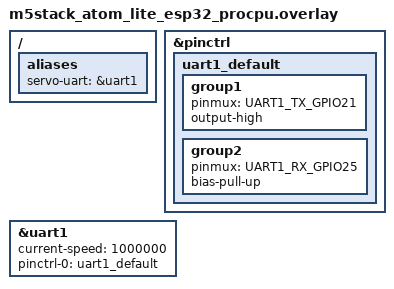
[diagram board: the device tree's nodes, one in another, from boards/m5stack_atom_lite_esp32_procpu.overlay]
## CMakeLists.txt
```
# SPDX-License-Identifier: Apache-2.0

cmake_minimum_required(VERSION 3.20.0)

# Find Zephyr. This also loads Zephyr's build system.
find_package(Zephyr REQUIRED HINTS $ENV{ZEPHYR_BASE})

project(octrobot_firmware VERSION 0.3.0 LANGUAGES C)

# Add application source files
target_sources(app PRIVATE
  src/main.c
)

# Add include directories
target_include_directories(app PRIVATE
  include
)

# HAL layer (Phase 2)
target_sources(app PRIVATE
  src/hal/half_duplex_uart.c
  src/hal/hal_gpio.c
  src/hal/hal_flash.c
)

# Servo driver (Phase 3)
target_sources(app PRIVATE
  src/drivers/feetech_protocol.c
  src/drivers/feetech_servo.c
)

# Host communications (Phase 3b)
target_sources(app PRIVATE
  src/comms/packet_protocol.c
  src/comms/host_comms.c
  src/comms/uart_console.c
)

# Kinematics (Phase 4 - POE implementation)
target_sources(app PRIVATE
  src/kinematics/kinematics_math.c
  src/kinematics/matrix_exp.c
  src/kinematics/robot_geometry.c
  src/kinematics/forward_kinematics_poe.c
  src/kinematics/inverse_kinematics_poe.c
)

# Trajectory planner (to be added in Phase 5)
# target_sources(app PRIVATE
#   src/trajectory/joint_trajectory.c
# )

# Motion controller (to be added in Phase 6)
target_sources(app PRIVATE
  src/controller/servo_control.c
  src/controller/joint_map.c
  src/controller/cartesian_pose.c
  src/controller/cartesian_move.c
)

# Host communications (to be added in Phase 7)
# target_sources(app PRIVATE
#   src/comms/host_comms.c
# )
```

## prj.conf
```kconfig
# OctroBot Robot Arm Firmware Configuration

# Kernel config
CONFIG_MAIN_STACK_SIZE=4096
CONFIG_SYSTEM_WORKQUEUE_STACK_SIZE=2048
CONFIG_HEAP_MEM_POOL_SIZE=8192

# Logging
CONFIG_LOG=y
CONFIG_LOG_DEFAULT_LEVEL=3
CONFIG_LOG_PRINTK=y
CONFIG_LOG_BACKEND_UART=y
CONFIG_CONSOLE=y
CONFIG_UART_CONSOLE=y
# Enable debug level logs for UART console output
CONFIG_UART_CONSOLE_LOG_LEVEL_DBG=y
CONFIG_LOG_MODE_IMMEDIATE=y

# Atom Lite ESP32-PICO-D4 may report chip revision v1.1; allow boot on this revision.
CONFIG_ESP32_USE_UNSUPPORTED_REVISION=y

# Host communication uses UART0 through the onboard CH340 USB-UART bridge
# (ESP32-PICO-D4 doesn't have native USB - only ESP32-S2/S3 have USB)

# UART (UART0 for host commands, UART1 for Feetech servo bus)
CONFIG_SERIAL=y
CONFIG_UART_INTERRUPT_DRIVEN=y

# GPIO (for direction control and emergency stop button)
CONFIG_GPIO=y

# Flash and NVS (Non-Volatile Storage)
CONFIG_FLASH=y
CONFIG_FLASH_MAP=y
CONFIG_NVS=y
CONFIG_NVS_LOG_LEVEL_DBG=y
CONFIG_MPU_ALLOW_FLASH_WRITE=y

# CRC (used by robot_geometry for NVS-stored POE model integrity)
CONFIG_CRC=y

# Timer and system clock
CONFIG_SYS_CLOCK_TICKS_PER_SEC=1000

# Math library support
CONFIG_NEWLIB_LIBC=y
CONFIG_NEWLIB_LIBC_FLOAT_PRINTF=y
CONFIG_NEWLIB_LIBC_FLOAT_SCANF=y

# Dual-core SMP configuration (Phase 4)
# DEBUG 2026-06-02: SMP/APP_CPU bring-up suspected of pre-kernel boot hang
# (RTC/TG0 watchdog loop, no console output). Disabled to isolate. Re-enable
# once dual-core boot is verified on hardware.
CONFIG_SMP=n
CONFIG_MP_MAX_NUM_CPUS=1

# Thread CPU affinity and pinning (selective pinning strategy)
# CONFIG_SCHED_CPU_MASK=y  # requires SMP; re-enable with SMP

# Hardware floating-point unit (critical for matrix operations in FK/IK)
CONFIG_FPU=y
CONFIG_FPU_SHARING=y

# Thread priorities and timing (to be tuned in Phase 6)
# CONFIG_NUM_PREEMPT_PRIORITIES=15

# Zephyr C standard
CONFIG_STD_C17=y
```

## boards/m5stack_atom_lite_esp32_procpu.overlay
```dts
/* Enable dedicated servo UART on Atom Lite (GPIO21 TX, GPIO25 RX). */

#include <zephyr/dt-bindings/pinctrl/esp-pinctrl-common.h>
#include <dt-bindings/pinctrl/esp32-pinctrl.h>

/ {
	aliases {
		servo-uart = &uart1;
	};
};

&pinctrl {
	uart1_default: uart1_default {
		group1 {
			pinmux = <UART1_TX_GPIO21>;
			output-high;
		};
		group2 {
			pinmux = <UART1_RX_GPIO25>;
			bias-pull-up;
		};
	};
};

&uart1 {
	status = "okay";
	current-speed = <1000000>;
	pinctrl-0 = <&uart1_default>;
	pinctrl-names = "default";
};
```

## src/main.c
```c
/*
 * OctroBot Robot Arm Firmware
 * Copyright (c) 2026 OctroBot Project
 *
 * SPDX-License-Identifier: Apache-2.0
 */

#include <inttypes.h>

#include <zephyr/kernel.h>
#include <zephyr/logging/log.h>
#include <zephyr/version.h>

#include "feetech_servo.h"
#include "hal_gpio.h"
#include "hal_flash.h"
#include "half_duplex_uart.h"
#include "uart_console.h"
#include "robot_geometry.h"
#include "forward_kinematics_poe.h"

LOG_MODULE_REGISTER(main, LOG_LEVEL_INF);

static volatile bool emergency_stop_active = false;

static void emergency_stop_callback(void)
{
	emergency_stop_active = true;
	LOG_ERR("!!! EMERGENCY STOP ACTIVATED !!!");

	/* Disable torque on all configured joints. */
	for (uint8_t id = 1; id <= 6; id++) {
		(void)feetech_servo_set_torque_enable(id, false);
	}
}

static int initialize_hal(void)
{
	int ret;

	LOG_INF("Initializing HAL layer...");

	ret = hal_gpio_button_init();
	if (ret == HAL_OK) {
		ret = hal_gpio_button_set_callback(emergency_stop_callback);
		if (ret != HAL_OK) {
			LOG_WRN("Button callback setup failed: %d", ret);
		}
	} else {
		LOG_WRN("Button init failed: %d", ret);
	}

	/* Initialize flash storage for persistent data */
	ret = hal_flash_init();
	if (ret != HAL_OK) {
		LOG_ERR("Failed to initialize flash storage: %d", ret);
		/* Non-fatal - continue without persistent storage */
	}

	struct half_duplex_uart_config uart_config = {
		.device_name = NULL,
		.baudrate = 1000000,
		.tx_timeout_ms = 100,
		.rx_timeout_ms = 50,
	};

	hal_uart_handle_t servo_uart = half_duplex_uart_init(&uart_config);
	if (!servo_uart) {
		LOG_ERR("Failed to initialize half-duplex UART");
		return HAL_ERROR;
	}

	ret = feetech_servo_init(servo_uart);
	if (ret != HAL_OK) {
		LOG_ERR("Failed to initialize servo driver: %d", ret);
		return ret;
	}

	LOG_INF("HAL layer initialized successfully");
	return HAL_OK;
}

static void test_servos(void)
{
	LOG_INF("===========================================");
	LOG_INF("Testing Servo Communication");
	LOG_INF("===========================================");

	uint8_t servo_ids[] = {1, 2, 3, 4, 5, 6};
	uint8_t servo_count = ARRAY_SIZE(servo_ids);
	uint8_t detected_servos = 0;

	LOG_INF("Pinging servos...");
	for (uint8_t i = 0; i < servo_count; i++) {
		int ret = feetech_servo_ping(servo_ids[i]);
		if (ret == HAL_OK) {
			LOG_INF("  Servo %d: OK", servo_ids[i]);
			detected_servos++;
		} else {
			LOG_WRN("  Servo %d: No response (%d)", servo_ids[i], ret);
		}
		k_msleep(50);
	}

	LOG_INF("Detected %d/%d servos", detected_servos, servo_count);
	if (detected_servos == 0) {
		LOG_ERR("No servos detected. Check wiring and power.");
		LOG_INF("  - Verify servos are powered (6-12V)");
		LOG_INF("  - Check UART connections (GPIO 21=TX, GPIO 25=RX)");
		LOG_INF("  - Confirm servo IDs are 1-6");
		LOG_INF("  - Verify baud rate is 1 Mbps");
		return;
	}

	LOG_INF("Reading initial servo positions...");
	for (uint8_t i = 0; i < servo_count; i++) {
		uint16_t position = 0;
		int ret = feetech_servo_read_position(servo_ids[i], &position);
		if (ret == HAL_OK) {
			float angle = FEETECH_POS_TO_DEG(position);
			LOG_INF("  Servo %d: position=%d (%.2f deg)", servo_ids[i], position,
				(double)angle);
		}
		k_msleep(50);
	}

	LOG_INF("Reading servo status...");
	for (uint8_t i = 0; i < servo_count; i++) {
		struct feetech_servo_state state;
		int ret = feetech_servo_read_state(servo_ids[i], &state);
		if (ret == HAL_OK) {
			LOG_INF("  Servo %d: temp=%dC, voltage=%d.%dV, load=%d", servo_ids[i],
				state.present_temperature, state.present_voltage / 10,
				state.present_voltage % 10, state.present_load);
		}
		k_msleep(100);
	}

	LOG_INF("===========================================");
	LOG_INF("Servo test complete");
	LOG_INF("===========================================");
}

static void test_forward_kinematics(void)
{
	LOG_INF("");
	LOG_INF("===========================================");
	LOG_INF("Testing Forward Kinematics (POE)");
	LOG_INF("===========================================");
	
	/* Initialize robot geometry (loads from flash or uses factory defaults) */
	robot_geometry_init();
	const poe_robot_model_t *model = robot_geometry_get_model();
	
	LOG_INF("Robot model loaded:");
	LOG_INF("  - Screw axes: 6 joints");
	LOG_INF("  - Home config: M matrix");
	LOG_INF("  - Joint limits configured");
	
	/* Test 1: Zero configuration (home position) */
	LOG_INF("");
	LOG_INF("Test 1: Zero configuration (home position)");
	float joint_angles_zero[NUM_JOINTS] = {0.0f, 0.0f, 0.0f, 0.0f, 0.0f, 0.0f};
	mat4x4_t T_zero;
	
	if (forward_kinematics_compute(model, joint_angles_zero, &T_zero)) {
		vec3_t pos = mat4x4_get_translation(&T_zero);
		LOG_INF("  FK([0,0,0,0,0,0]):");
		LOG_INF("    Position: [%.4f, %.4f, %.4f] m", 
		        (double)pos.x, (double)pos.y, (double)pos.z);
		LOG_INF("    (Should match home configuration M)");
	} else {
		LOG_ERR("  FK computation failed!");
	}
	
	/* Test 2: Small joint movements */
	LOG_INF("");
	LOG_INF("Test 2: Small joint movements");
	float joint_angles_30deg[NUM_JOINTS] = {
		deg_to_rad(30.0f),   /* Base rotation 30° */
		deg_to_rad(0.0f),    /* Shoulder */
		deg_to_rad(0.0f),    /* Elbow */
		deg_to_rad(0.0f),    /* Wrist roll */
		deg_to_rad(0.0f),    /* Wrist pitch */
		deg_to_rad(0.0f)     /* Wrist roll */
	};
	mat4x4_t T_30deg;
	
	if (forward_kinematics_compute(model, joint_angles_30deg, &T_30deg)) {
		vec3_t pos = mat4x4_get_translation(&T_30deg);
		LOG_INF("  FK([30°,0,0,0,0,0]):");
		LOG_INF("    Position: [%.4f, %.4f, %.4f] m", 
		        (double)pos.x, (double)pos.y, (double)pos.z);
		LOG_INF("    (Base rotated 30°, end-effector should move in XY plane)");
	} else {
		LOG_ERR("  FK computation failed!");
	}
	
	/* Test 3: Multiple joint movements */
	LOG_INF("");
	LOG_INF("Test 3: Multiple joint movements");
	float joint_angles_multi[NUM_JOINTS] = {
		deg_to_rad(45.0f),   /* Base 45° */
		deg_to_rad(30.0f),   /* Shoulder 30° */
		deg_to_rad(-20.0f),  /* Elbow -20° */
		deg_to_rad(0.0f),    /* Wrist roll */
		deg_to_rad(15.0f),   /* Wrist pitch 15° */
		deg_to_rad(0.0f)     /* Wrist roll */
	};
	mat4x4_t T_multi;
	
	if (forward_kinematics_compute(model, joint_angles_multi, &T_multi)) {
		vec3_t pos = mat4x4_get_translation(&T_multi);
		mat3x3_t rot = mat4x4_get_rotation(&T_multi);
		LOG_INF("  FK([45°,30°,-20°,0°,15°,0°]):");
		LOG_INF("    Position: [%.4f, %.4f, %.4f] m", 
		        (double)pos.x, (double)pos.y, (double)pos.z);
		LOG_INF("    Rotation matrix:");
		LOG_INF("      [%.3f, %.3f, %.3f]", 
		        (double)rot.m[0][0], (double)rot.m[0][1], (double)rot.m[0][2]);
		LOG_INF("      [%.3f, %.3f, %.3f]", 
		        (double)rot.m[1][0], (double)rot.m[1][1], (double)rot.m[1][2]);
		LOG_INF("      [%.3f, %.3f, %.3f]", 
		        (double)rot.m[2][0], (double)rot.m[2][1], (double)rot.m[2][2]);
	} else {
		LOG_ERR("  FK computation failed!");
	}
	
	/* Test 4: Partial FK (intermediate link positions) */
	LOG_INF("");
	LOG_INF("Test 4: Partial FK (joint 2 position)");
	mat4x4_t T_partial;
	
	if (forward_kinematics_partial(model, joint_angles_multi, 2, &T_partial)) {
		vec3_t pos = mat4x4_get_translation(&T_partial);
		LOG_INF("  FK_partial([45°,30°,-20°,...], end_idx=2):");
		LOG_INF("    Joint 2 position: [%.4f, %.4f, %.4f] m", 
		        (double)pos.x, (double)pos.y, (double)pos.z);
		LOG_INF("    (Position after joints 0-2)");
	} else {
		LOG_ERR("  Partial FK computation failed!");
	}
	
	/* Test 5: Performance measurement */
	LOG_INF("");
	LOG_INF("Test 5: Performance measurement");
	uint32_t start_time = k_cycle_get_32();
	const int num_iterations = 100;
	
	for (int i = 0; i < num_iterations; i++) {
		mat4x4_t T_perf;
		forward_kinematics_compute(model, joint_angles_multi, &T_perf);
	}
	
	uint32_t end_time = k_cycle_get_32();
	uint32_t cycles = end_time - start_time;
	uint32_t cycles_per_fk = cycles / num_iterations;
	
	/* ESP32 @ 240MHz: 1 cycle = 1/240MHz ≈ 4.17 ns */
	float time_per_fk_us = (float)cycles_per_fk / 240.0f;  /* μs */
	
	LOG_INF("  FK computation time:");
	LOG_INF("    %d iterations: %u cycles", num_iterations, cycles);
	LOG_INF("    Average: %u cycles/FK (%.2f μs)", 
	        cycles_per_fk, (double)time_per_fk_us);
	LOG_INF("    Expected: 2000-5000 μs (2-5 ms)");
	
	if (time_per_fk_us < 10000.0f) {  /* Less than 10ms */
		LOG_INF("    ✓ Performance is good!");
	} else {
		LOG_WRN("    ⚠ Performance is slower than expected");
	}
	
	LOG_INF("");
	LOG_INF("===========================================");
	LOG_INF("Forward Kinematics test complete");
	LOG_INF("===========================================");
}

int main(void)
{
	int ret;

	LOG_INF("===========================================");
	LOG_INF("OctroBot Robot Arm Firmware v0.3.0");
	LOG_INF("===========================================");
	LOG_INF("MCU: ESP32-PICO-D4 (M5Stack Atom Lite)");
	LOG_INF("RTOS: Zephyr RTOS v%s", KERNEL_VERSION_STRING);
	LOG_INF("Build: %s %s", __DATE__, __TIME__);
	LOG_INF("Console: UART0 via CH340 USB-UART bridge");
	LOG_INF("===========================================");

	ret = initialize_hal();
	if (ret != HAL_OK) {
		LOG_ERR("HAL initialization failed: %d", ret);
		return ret;
	}

	LOG_INF("System initialization complete");
	LOG_INF("6-DOF robot arm ready");
	LOG_INF("Press button (GPIO 39) for emergency stop");

	k_sleep(K_MSEC(500));
	test_servos();
	
	/* Test forward kinematics (Phase 4) */
	k_sleep(K_MSEC(500));
	test_forward_kinematics();

	/* Initialize host communication */
	ret = uart_console_init();
	if (ret == 0) {
		LOG_INF("Host communication initialized");
		LOG_INF("Connect via USB serial to send commands");
	} else {
		LOG_WRN("Host communication init failed: %d", ret);
		LOG_INF("Continuing without host control...");
	}

	LOG_INF("");
	LOG_INF("===========================================");
	LOG_INF("Entering main loop - Phase 3b Manual Control");
	LOG_INF("===========================================");
	LOG_INF("Send commands via USB serial to control robot");
	LOG_INF("Available commands:");
	LOG_INF("  - jog: Move joints incrementally");
	LOG_INF("  - set: Direct position control");
	LOG_INF("  - read: Get current joint angles");
	LOG_INF("  - demo: Record and playback motions");
	LOG_INF("===========================================");
	LOG_INF("");

	while (1) {
		// Heartbeat message every 5 seconds
		LOG_DBG("Main loop heartbeat");
		k_sleep(K_MSEC(5000));
	}

	return 0;
}
```

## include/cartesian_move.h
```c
/*
 * OctroBot Robot Arm Firmware - Cartesian Move-to-Pose (hardware wrapper)
 * Copyright (c) 2026 OctroBot Project
 *
 * SPDX-License-Identifier: Apache-2.0
 *
 * Drives the arm to a commanded Cartesian pose: checks e-stop, reads the
 * current servo angles for the IK seed, runs cartesian_pose_to_joints, maps the
 * solution to servo degrees, range-checks, and sync-writes goal angles with an
 * onboard move time. RPY is ZYX intrinsic (degrees); position in meters.
 */

#ifndef CARTESIAN_MOVE_H
#define CARTESIAN_MOVE_H

#include <stdint.h>
#include "cartesian_pose.h"   /* cmove_status_t */

#ifdef __cplusplus
extern "C" {
#endif

/**
 * Move the arm to a Cartesian pose.
 *
 * @param x,y,z       target position in meters (model frame)
 * @param roll_deg,pitch_deg,yaw_deg  target orientation, ZYX intrinsic, degrees
 * @param move_time_ms  servo move duration in ms (onboard smoothing)
 * @return cmove_status_t (CMOVE_OK on success; no motion is commanded on any
 *         non-OK status)
 */
cmove_status_t cartesian_move_to_pose(float x, float y, float z,
				      float roll_deg, float pitch_deg,
				      float yaw_deg, uint16_t move_time_ms);

#ifdef __cplusplus
}
#endif

#endif /* CARTESIAN_MOVE_H */
```

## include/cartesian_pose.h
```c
/*
 * OctroBot Robot Arm Firmware - Cartesian Pose -> Joints (pure core)
 * Copyright (c) 2026 OctroBot Project
 *
 * SPDX-License-Identifier: Apache-2.0
 *
 * Pure (hardware-free) conversion of a commanded Cartesian pose into
 * model-frame joint angles via the IK solver. RPY uses the ZYX intrinsic
 * convention; angles in degrees, position in meters.
 */

#ifndef CARTESIAN_POSE_H
#define CARTESIAN_POSE_H

#include "robot_geometry.h"   /* poe_robot_model_t, NUM_JOINTS */

#ifdef __cplusplus
extern "C" {
#endif

/** Result of a Cartesian move-to-pose request. */
typedef enum {
	CMOVE_OK = 0,         /* solved (and, in the wrapper, motion sent)     */
	CMOVE_NO_SOLUTION,    /* IK did not converge                           */
	CMOVE_OUT_OF_LIMITS,  /* solution violates joint/servo limits          */
	CMOVE_ESTOP,          /* emergency stop active (wrapper only)          */
	CMOVE_SERVO_ERR,      /* servo read/write failure (wrapper only)       */
	CMOVE_BAD_ARGS,       /* NULL/invalid argument                         */
} cmove_status_t;

/**
 * Compute model-frame joint angles for a Cartesian pose.
 *
 * @param model       robot geometry
 * @param x,y,z       target position in meters (model frame)
 * @param roll_deg,pitch_deg,yaw_deg  target orientation, ZYX intrinsic, degrees
 * @param seed_theta  IK initial guess (model radians)
 * @param out_theta   solved joint angles (model radians)
 * @param iters_used  if non-NULL, receives the IK iteration count (debug)
 * @return CMOVE_OK / CMOVE_NO_SOLUTION / CMOVE_OUT_OF_LIMITS / CMOVE_BAD_ARGS.
 *         out_theta is written on both CMOVE_OK and CMOVE_OUT_OF_LIMITS (the
 *         final IK iterate); it is left untouched on the other statuses.
 *         Callers must not command motion unless the status is CMOVE_OK.
 */
cmove_status_t cartesian_pose_to_joints(const poe_robot_model_t *model,
					float x, float y, float z,
					float roll_deg, float pitch_deg,
					float yaw_deg,
					const float seed_theta[NUM_JOINTS],
					float out_theta[NUM_JOINTS],
					int *iters_used);

#ifdef __cplusplus
}
#endif

#endif /* CARTESIAN_POSE_H */
```

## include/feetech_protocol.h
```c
/*
 * OctroBot Robot Arm Firmware - Feetech SCS/STS Protocol
 * Copyright (c) 2026 OctroBot Project
 *
 * SPDX-License-Identifier: Apache-2.0
 *
 * Protocol implementation for Feetech Serial Control System (SCS) and
 * Serial Torque Servo (STS) servos.
 *
 * Packet Format:
 *   [0xFF] [0xFF] [ID] [LENGTH] [INSTRUCTION] [PARAMS...] [CHECKSUM]
 *
 * Checksum: ~(ID + LENGTH + INSTRUCTION + PARAMS) & 0xFF
 */

#ifndef OCTROBOT_FEETECH_PROTOCOL_H
#define OCTROBOT_FEETECH_PROTOCOL_H

#include "hal_types.h"
#include "half_duplex_uart.h"

/* Protocol constants */
#define FEETECH_HEADER_1          0xFF
#define FEETECH_HEADER_2          0xFF
#define FEETECH_BROADCAST_ID      0xFE
#define FEETECH_MIN_PACKET_SIZE   6

/* Instruction set */
#define FEETECH_INST_PING         0x01
#define FEETECH_INST_READ         0x02
#define FEETECH_INST_WRITE        0x03
#define FEETECH_INST_REG_WRITE    0x04
#define FEETECH_INST_ACTION       0x05
#define FEETECH_INST_SYNC_WRITE   0x83
#define FEETECH_INST_SYNC_READ    0x84

/* Common register addresses (STS series) */
#define FEETECH_REG_ID                    0x05
#define FEETECH_REG_BAUD_RATE             0x06
#define FEETECH_REG_RETURN_DELAY          0x07
#define FEETECH_REG_RESPONSE_STATUS       0x08
#define FEETECH_REG_MIN_ANGLE_LIMIT_L     0x09
#define FEETECH_REG_MIN_ANGLE_LIMIT_H     0x0A
#define FEETECH_REG_MAX_ANGLE_LIMIT_L     0x0B
#define FEETECH_REG_MAX_ANGLE_LIMIT_H     0x0C
#define FEETECH_REG_MAX_TEMPERATURE       0x0D
#define FEETECH_REG_MAX_VOLTAGE           0x0E
#define FEETECH_REG_MIN_VOLTAGE           0x0F
#define FEETECH_REG_MAX_TORQUE_L          0x10
#define FEETECH_REG_MAX_TORQUE_H          0x11
#define FEETECH_REG_UNLOAD_CONDITION      0x13
#define FEETECH_REG_LED_ALARM             0x14
#define FEETECH_REG_P_COEFFICIENT         0x15
#define FEETECH_REG_D_COEFFICIENT         0x16
#define FEETECH_REG_I_COEFFICIENT         0x17
#define FEETECH_REG_MINIMUM_STARTUP_FORCE_L 0x18
#define FEETECH_REG_MINIMUM_STARTUP_FORCE_H 0x19
#define FEETECH_REG_TORQUE_ENABLE         0x28
#define FEETECH_REG_ACCELERATION          0x29
#define FEETECH_REG_GOAL_POSITION_L       0x2A
#define FEETECH_REG_GOAL_POSITION_H       0x2B
#define FEETECH_REG_GOAL_TIME_L           0x2C
#define FEETECH_REG_GOAL_TIME_H           0x2D
#define FEETECH_REG_GOAL_SPEED_L          0x2E
#define FEETECH_REG_GOAL_SPEED_H          0x2F
#define FEETECH_REG_TORQUE_LIMIT_L        0x30
#define FEETECH_REG_TORQUE_LIMIT_H        0x31
#define FEETECH_REG_LOCK                  0x37
#define FEETECH_REG_PRESENT_POSITION_L    0x38
#define FEETECH_REG_PRESENT_POSITION_H    0x39
#define FEETECH_REG_PRESENT_SPEED_L       0x3A
#define FEETECH_REG_PRESENT_SPEED_H       0x3B
#define FEETECH_REG_PRESENT_LOAD_L        0x3C
#define FEETECH_REG_PRESENT_LOAD_H        0x3D
#define FEETECH_REG_PRESENT_VOLTAGE       0x3E
#define FEETECH_REG_PRESENT_TEMPERATURE   0x3F
#define FEETECH_REG_REGISTERED            0x40
#define FEETECH_REG_STATUS                0x41
#define FEETECH_REG_MOVING                0x42
#define FEETECH_REG_VIR_POSITION_L        0x46
#define FEETECH_REG_VIR_POSITION_H        0x47
#define FEETECH_REG_CURRENT_L             0x45
#define FEETECH_REG_CURRENT_H             0x69

/* Error codes in response packets */
#define FEETECH_ERROR_VOLTAGE       (1 << 0)
#define FEETECH_ERROR_ANGLE_LIMIT   (1 << 1)
#define FEETECH_ERROR_OVERHEAT      (1 << 2)
#define FEETECH_ERROR_RANGE         (1 << 3)
#define FEETECH_ERROR_CHECKSUM      (1 << 4)
#define FEETECH_ERROR_OVERLOAD      (1 << 5)
#define FEETECH_ERROR_INSTRUCTION   (1 << 6)

/* Maximum packet size */
#define FEETECH_MAX_PACKET_SIZE   256

/**
 * @brief Feetech packet structure
 */
struct feetech_packet {
	uint8_t id;
	uint8_t instruction;
	uint8_t error;
	uint8_t parameters[FEETECH_MAX_PACKET_SIZE];
	uint8_t param_length;
};

/**
 * @brief Calculate checksum for Feetech packet
 *
 * @param id Servo ID
 * @param length Packet length (instruction + params + 1)
 * @param instruction Instruction byte
 * @param params Parameter bytes
 * @param param_len Number of parameter bytes
 * @return Calculated checksum
 */
uint8_t feetech_protocol_calculate_checksum(uint8_t id, uint8_t length, uint8_t instruction,
                                    const uint8_t *params, uint8_t param_len);

/**
 * @brief Build a Feetech instruction packet
 *
 * @param packet Pointer to packet structure
 * @param buffer Output buffer for raw packet bytes
 * @param buffer_size Size of output buffer
 * @return Number of bytes written to buffer, or negative error code
 */
int feetech_protocol_build_packet(const struct feetech_packet *packet, uint8_t *buffer,
                         size_t buffer_size);

/**
 * @brief Parse a Feetech response packet
 *
 * @param buffer Input buffer containing raw packet bytes
 * @param buffer_len Length of input buffer
 * @param packet Pointer to packet structure to fill
 * @return HAL_OK on success, error code otherwise
 */
int feetech_protocol_parse_packet(const uint8_t *buffer, size_t buffer_len,
                         struct feetech_packet *packet);

/**
 * @brief Send a ping to servo and wait for response
 *
 * @param uart UART handle
 * @param id Servo ID
 * @return HAL_OK if servo responds, error code otherwise
 */
int feetech_protocol_ping(hal_uart_handle_t uart, uint8_t id);

/**
 * @brief Read data from servo register
 *
 * @param uart UART handle
 * @param id Servo ID
 * @param reg_addr Register address
 * @param length Number of bytes to read
 * @param data Output buffer for read data
 * @return HAL_OK on success, error code otherwise
 */
int feetech_protocol_read(hal_uart_handle_t uart, uint8_t id, uint8_t reg_addr,
                 uint8_t length, uint8_t *data);

/**
 * @brief Write data to servo register
 *
 * @param uart UART handle
 * @param id Servo ID
 * @param reg_addr Register address
 * @param data Data to write
 * @param length Number of bytes to write
 * @return HAL_OK on success, error code otherwise
 */
int feetech_protocol_write(hal_uart_handle_t uart, uint8_t id, uint8_t reg_addr,
                  const uint8_t *data, uint8_t length);

/**
 * @brief Sync write to multiple servos (single register)
 *
 * @param uart UART handle
 * @param reg_addr Starting register address
 * @param data_len Length of data per servo
 * @param servo_ids Array of servo IDs
 * @param servo_data Array of data for each servo (servo_count * data_len bytes)
 * @param servo_count Number of servos
 * @return HAL_OK on success, error code otherwise
 */
int feetech_protocol_sync_write(hal_uart_handle_t uart, uint8_t reg_addr, uint8_t data_len,
                       const uint8_t *servo_ids, const uint8_t *servo_data,
                       uint8_t servo_count);

/**
 * @brief Read 16-bit value from servo (little-endian)
 *
 * @param uart UART handle
 * @param id Servo ID
 * @param reg_addr Register address (low byte)
 * @param value Pointer to store 16-bit value
 * @return HAL_OK on success, error code otherwise
 */
int feetech_protocol_read_word(hal_uart_handle_t uart, uint8_t id, uint8_t reg_addr,
                      uint16_t *value);

/**
 * @brief Write 16-bit value to servo (little-endian)
 *
 * @param uart UART handle
 * @param id Servo ID
 * @param reg_addr Register address (low byte)
 * @param value 16-bit value to write
 * @return HAL_OK on success, error code otherwise
 */
int feetech_protocol_write_word(hal_uart_handle_t uart, uint8_t id, uint8_t reg_addr,
                       uint16_t value);

#endif /* OCTROBOT_FEETECH_PROTOCOL_H */
```

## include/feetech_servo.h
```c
/*
 * OctroBot Robot Arm Firmware - Feetech Servo Driver
 * Copyright (c) 2026 OctroBot Project
 *
 * SPDX-License-Identifier: Apache-2.0
 *
 * High-level servo control API for Feetech SCS/STS servos.
 */

#ifndef OCTROBOT_FEETECH_SERVO_H
#define OCTROBOT_FEETECH_SERVO_H

#include "hal_types.h"
#include "half_duplex_uart.h"

/* Servo position range (typical for STS3215) */
#define FEETECH_POS_MIN      0
#define FEETECH_POS_MAX      4095
#define FEETECH_POS_CENTER   2048

/* Convert between servo ticks and degrees */
#define FEETECH_POS_TO_DEG(pos)   (((float)(pos) - FEETECH_POS_CENTER) * (360.0f / 4096.0f))
#define FEETECH_DEG_TO_POS(deg)   ((uint16_t)(((deg) * (4096.0f / 360.0f)) + FEETECH_POS_CENTER))

/* Velocity range (typical for STS3215) */
#define FEETECH_VEL_MIN      0
#define FEETECH_VEL_MAX      4095
#define FEETECH_DEFAULT_SPEED 1000  /* Default speed in steps/second (~50% max) */

/* Speed clamp for time-based moves. These servos move under GOAL_SPEED, not
 * GOAL_TIME, and a speed of 0 means "hold" (no motion). The floor guarantees
 * even tiny moves actuate; the cap keeps bring-up moves gentle. */
#define FEETECH_TIMED_SPEED_MIN  50
#define FEETECH_TIMED_SPEED_MAX  2000

/* Maximum number of servos in robot */
#define FEETECH_MAX_SERVOS   6

/**
 * @brief Servo configuration structure
 */
struct feetech_servo_config {
	uint8_t id;                     /* Servo ID (1-253) */
	uint16_t pos_min;               /* Minimum position limit (ticks) */
	uint16_t pos_max;               /* Maximum position limit (ticks) */
	uint16_t pos_offset;            /* Position offset for calibration */
	bool reverse;                   /* Reverse direction flag */
};

/**
 * @brief Servo state structure
 */
struct feetech_servo_state {
	uint16_t present_position;      /* Current position (ticks) */
	uint16_t present_speed;         /* Current speed */
	uint16_t present_load;          /* Current load */
	uint8_t present_voltage;        /* Current voltage (0.1V units) */
	uint8_t present_temperature;    /* Current temperature (°C) */
	bool is_moving;                 /* Movement status */
	bool is_torque_enabled;         /* Torque status */
	uint8_t error;                  /* Error flags */
};

/**
 * @brief Initialize Feetech servo driver
 *
 * @param uart UART handle for servo communication
 * @return HAL_OK on success, error code otherwise
 */
int feetech_servo_init(hal_uart_handle_t uart);

/**
 * @brief Ping servo to check if it's responding
 *
 * @param id Servo ID
 * @return HAL_OK if servo responds, error code otherwise
 */
int feetech_servo_ping(uint8_t id);

/**
 * @brief Enable/disable servo torque
 *
 * @param id Servo ID
 * @param enable true to enable torque, false to disable
 * @return HAL_OK on success, error code otherwise
 */
int feetech_servo_set_torque_enable(uint8_t id, bool enable);

/**
 * @brief Check if servo torque is currently enabled
 * @param id Servo ID
 * @return true if torque is enabled, false if disabled or on error
 */
bool feetech_servo_is_torque_enabled(uint16_t id);

/**
 * @brief Set torque limit for servo at runtime instead of using EEPROM settings
 * @param id Servo ID
 * @param max_torque Maximum torque (0-1000, where 1000 = 100%)
 * @return HAL_OK on success, error code otherwise
 */
int feetech_servo_set_torque_limit(uint8_t id, uint16_t max_torque);

/**
 * @brief Read current torque limit setting from servo
 * @param id Servo ID
 * @param max_torque Pointer to store maximum torque (0-1000, where 1000 = 100%)
 * @return HAL_OK on success, error code otherwise
 */
int feetech_servo_read_torque_limit(uint8_t id, uint16_t *max_torque);

/**
 * @brief Set servo goal position (in ticks)
 *
 * Sets goal position with default time (0 = immediate) and default speed
 * (FEETECH_DEFAULT_SPEED = 2000 steps/second).
 * Uses optimized 6-byte write per Feetech protocol (0x2A-0x2F).
 *
 * @param id Servo ID
 * @param position Goal position (0-4095)
 * @return HAL_OK on success, error code otherwise
 */
int feetech_servo_set_goal_position(uint8_t id, uint16_t position);

/**
 * @brief Set servo goal position with time and speed control (extended)
 *
 * Sets position, time, and speed in single 6-byte write to 0x2A-0x2F
 * per Feetech protocol. More efficient than separate writes.
 *
 * @param id Servo ID
 * @param position Goal position (0-4095)
 * @param time_ms Time to reach position in milliseconds (0 = immediate)
 * @param speed Maximum speed during movement in steps/second (0 = no limit)
 * @return HAL_OK on success, error code otherwise
 */
int feetech_servo_set_goal_position_ex(uint8_t id, uint16_t position,
                                        uint16_t time_ms, uint16_t speed);

/**
 * @brief Set servo goal position (in degrees)
 *
 * @param id Servo ID
 * @param angle Goal angle in degrees (-180 to +180)
 * @return HAL_OK on success, error code otherwise
 */
int feetech_servo_set_goal_angle(uint8_t id, float angle);

/**
 * @brief Set servo goal speed
 *
 * @param id Servo ID
 * @param speed Goal speed (0-4095)
 * @return HAL_OK on success, error code otherwise
 */
int feetech_servo_set_goal_speed(uint8_t id, uint16_t speed);

/**
 * @brief Set servo goal time (trajectory duration)
 *
 * @param id Servo ID
 * @param time_ms Goal time in milliseconds
 * @return HAL_OK on success, error code otherwise
 */
int feetech_servo_set_goal_time(uint8_t id, uint16_t time_ms);

/**
 * @brief Set servo acceleration
 *
 * @param id Servo ID
 * @param acceleration Acceleration value (0-254)
 * @return HAL_OK on success, error code otherwise
 */
int feetech_servo_set_acceleration(uint8_t id, uint8_t acceleration);

/**
 * @brief Read servo current position (in ticks)
 *
 * @param id Servo ID
 * @param position Pointer to store position
 * @return HAL_OK on success, error code otherwise
 */
int feetech_servo_read_position(uint8_t id, uint16_t *position);

/**
 * @brief Read servo current position (in degrees)
 *
 * @param id Servo ID
 * @param angle Pointer to store angle in degrees
 * @return HAL_OK on success, error code otherwise
 */
int feetech_servo_read_angle(uint8_t id, float *angle);

/**
 * @brief Read servo load (torque feedback)
 *
 * @param id Servo ID
 * @param load Pointer to store load value
 * @return HAL_OK on success, error code otherwise
 */
int feetech_servo_read_load(uint8_t id, uint16_t *load);

/**
 * @brief Read servo temperature
 *
 * @param id Servo ID
 * @param temperature Pointer to store temperature (°C)
 * @return HAL_OK on success, error code otherwise
 */
int feetech_servo_read_temperature(uint8_t id, uint8_t *temperature);

/**
 * @brief Read servo voltage
 *
 * @param id Servo ID
 * @param voltage Pointer to store voltage (0.1V units)
 * @return HAL_OK on success, error code otherwise
 */
int feetech_servo_read_voltage(uint8_t id, uint8_t *voltage);

/**
 * @brief Read servo status
 *
 * @param id Servo ID
 * @param status Pointer to store status byte
 * @return HAL_OK on success, error code otherwise
 */
int feetech_servo_read_status(uint8_t id, uint8_t *status);

/**
 * @brief Read full servo state
 *
 * @param id Servo ID
 * @param state Pointer to state structure to fill
 * @return HAL_OK on success, error code otherwise
 */
int feetech_servo_read_state(uint8_t id, struct feetech_servo_state *state);

/**
 * @brief Read states of multiple servos
 *
 * @param ids Array of servo IDs
 * @param states Array of state structures to fill
 * @param count Number of servos (max FEETECH_MAX_SERVOS)
 * @return HAL_OK on success, error code otherwise
 */
int feetech_servo_read_multi_states(const uint8_t *ids, struct feetech_servo_state *states,
									uint8_t count);

/**
 * @brief Synchronized write - set goal positions for multiple servos
 *
 * Sends goal positions to all servos in a single packet for coordinated motion.
 * This is critical for smooth robot arm movement.
 *
 * @param ids Array of servo IDs
 * @param positions Array of goal positions (ticks)
 * @param count Number of servos (max FEETECH_MAX_SERVOS)
 * @return HAL_OK on success, error code otherwise
 */
int feetech_servo_sync_write_positions(const uint8_t *ids, const uint16_t *positions,
                                        uint8_t count);

/**
 * @brief Synchronized write - set goal angles for multiple servos (degrees)
 *
 * @param ids Array of servo IDs
 * @param angles Array of goal angles in degrees
 * @param count Number of servos (max FEETECH_MAX_SERVOS)
 * @return HAL_OK on success, error code otherwise
 */
int feetech_servo_sync_write_angles(const uint8_t *ids, const float *angles,
                                     uint8_t count);

/**
 * @brief Sync-write goal positions to multiple servos with a move time.
 *        Unlike feetech_servo_sync_write_positions (immediate), this packs the
 *        servo running-time field so the move spans time_ms.
 * @param count Number of servos (max FEETECH_MAX_SERVOS)
 * @return 0 (HAL_OK) on success, negative on error
 */
int feetech_servo_sync_write_positions_timed(const uint8_t *ids,
                                             const uint16_t *positions,
                                             uint8_t count, uint16_t time_ms);

/**
 * @brief Sync-write goal angles (degrees) to multiple servos with a move time.
 * @param count Number of servos (max FEETECH_MAX_SERVOS)
 * @return 0 (HAL_OK) on success, negative on error
 */
int feetech_servo_sync_write_angles_timed(const uint8_t *ids,
                                          const float *angles,
                                          uint8_t count, uint16_t time_ms);

/**
 * @brief Block until all listed servos report stopped (MOVING flag clear).
 *        Adds a short startup settle so a just-issued move is not mistaken for
 *        "already stopped". The timeout bounds the wait if a MOVING flag is
 *        flaky; callers should proceed regardless of the return value.
 * @param ids        servo IDs to watch
 * @param count      number of servos (max FEETECH_MAX_SERVOS)
 * @param timeout_ms max time to wait after the startup settle
 * @return HAL_OK if all stopped, HAL_TIMEOUT if the timeout elapsed first,
 *         HAL_INVALID on bad arguments
 */
int feetech_servo_wait_until_stopped(const uint8_t *ids, uint8_t count,
                                     uint16_t timeout_ms);

/**
 * @brief Read positions from multiple servos
 *
 * @param ids Array of servo IDs
 * @param positions Array to store positions
 * @param count Number of servos
 * @return HAL_OK on success, error code otherwise
 */
int feetech_servo_read_multi_positions(const uint8_t *ids, uint16_t *positions,
                                        uint8_t count);

#endif /* OCTROBOT_FEETECH_SERVO_H */
```

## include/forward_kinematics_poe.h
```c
/*
 * OctroBot Robot Arm Firmware - Forward Kinematics (POE)
 * Copyright (c) 2026 OctroBot Project
 *
 * SPDX-License-Identifier: Apache-2.0
 *
 * Forward kinematics using Product of Exponentials (POE) formula:
 *   FK(θ) = exp([ξ₁]θ₁) · exp([ξ₂]θ₂) · ... · exp([ξ₆]θ₆) · M
 * 
 * Computational complexity: O(n) matrix multiplications (6× 4x4 matrices)
 * Expected runtime: 2-5ms on ESP32 @ 240MHz with FPU
 */

#ifndef FORWARD_KINEMATICS_POE_H
#define FORWARD_KINEMATICS_POE_H

#include "kinematics_math.h"
#include "robot_geometry.h"
#include <stdint.h>
#include <stdbool.h>

#ifdef __cplusplus
extern "C" {
#endif

/* ========================================================================
 * Forward Kinematics API
 * ======================================================================== */

/**
 * Compute forward kinematics using POE formula
 * 
 * Computes end-effector pose T ∈ SE(3) from joint angles θ:
 *   T(θ) = exp([ξ₁]θ₁) · exp([ξ₂]θ₂) · ... · exp([ξ₆]θ₆) · M
 * 
 * Inputs:
 *   - model: Robot geometric parameters (screw axes, home config)
 *   - joint_angles: Array of 6 joint angles (radians)
 * 
 * Output:
 *   - T: 4x4 homogeneous transformation matrix (end-effector pose)
 * 
 * Returns:
 *   - true: Computation successful
 *   - false: Invalid inputs
 * 
 * Performance: ~2-5ms on ESP32 @ 240MHz
 */
bool forward_kinematics_compute(const poe_robot_model_t *model,
                                 const float joint_angles[NUM_JOINTS],
                                 mat4x4_t *T);

/**
 * Compute forward kinematics with position and orientation extraction
 * 
 * Convenience function that computes FK and extracts:
 *   - Position: (x, y, z) in meters
 *   - Orientation: 3x3 rotation matrix
 * 
 * Inputs:
 *   - model: Robot geometric parameters
 *   - joint_angles: Array of 6 joint angles (radians)
 * 
 * Outputs:
 *   - position: End-effector position (vec3)
 *   - orientation: End-effector orientation (mat3x3)
 * 
 * Returns:
 *   - true: Computation successful
 *   - false: Invalid inputs
 */
bool forward_kinematics_compute_pose(const poe_robot_model_t *model,
                                      const float joint_angles[NUM_JOINTS],
                                      vec3_t *position,
                                      mat3x3_t *orientation);

/**
 * Compute forward kinematics for partial chain
 * 
 * Computes transformation from base to joint i:
 *   T_i(θ) = exp([ξ₁]θ₁) · ... · exp([ξᵢ]θᵢ) · M
 * 
 * Useful for:
 *   - Collision checking
 *   - Jacobian computation
 *   - Visualization of intermediate frames
 * 
 * Inputs:
 *   - model: Robot geometric parameters
 *   - joint_angles: Array of joint angles (only first end_joint_idx used)
 *   - end_joint_idx: Index of last joint to include (0-5)
 * 
 * Output:
 *   - T: Transformation to joint i
 * 
 * Returns:
 *   - true: Computation successful
 *   - false: Invalid inputs
 */
bool forward_kinematics_partial(const poe_robot_model_t *model,
                                 const float joint_angles[NUM_JOINTS],
                                 int end_joint_idx,
                                 mat4x4_t *T);

#ifdef __cplusplus
}
#endif

#endif /* FORWARD_KINEMATICS_POE_H */
```

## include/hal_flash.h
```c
/*
 * OctroBot Robot Arm Firmware - Flash HAL
 * Copyright (c) 2026 OctroBot Project
 *
 * SPDX-License-Identifier: Apache-2.0
 *
 * Flash storage abstraction layer for persistent data.
 * Uses Zephyr NVS (Non-Volatile Storage) subsystem.
 */

#ifndef OCTROBOT_HAL_FLASH_H
#define OCTROBOT_HAL_FLASH_H

#include "hal_types.h"

#ifdef __cplusplus
extern "C" {
#endif

/**
 * @brief Initialize flash storage subsystem
 * 
 * This function initializes the NVS subsystem and mounts the storage partition.
 * Should be called once during system initialization.
 * 
 * @return HAL_OK on success, error code otherwise
 */
int hal_flash_init(void);

/**
 * @brief Write data to flash storage
 * 
 * Writes data associated with a key to non-volatile storage.
 * If the key already exists, it will be overwritten.
 * 
 * Educational Note:
 * Flash wear leveling is handled automatically by the NVS subsystem.
 * The ESP32 flash has ~100k erase cycles per sector.
 * 
 * @param key Unique identifier for the data (e.g., "demo0", "demo1")
 * @param data Pointer to data buffer to write
 * @param len Length of data in bytes (max 8KB recommended)
 * @return HAL_OK on success, error code otherwise
 */
int hal_flash_write(const char *key, const void *data, size_t len);

/**
 * @brief Read data from flash storage
 * 
 * Reads data associated with a key from non-volatile storage.
 * 
 * @param key Unique identifier for the data
 * @param data Pointer to buffer to receive data
 * @param len Length of buffer (must be >= stored data size)
 * @return Number of bytes read on success, error code otherwise
 */
int hal_flash_read(const char *key, void *data, size_t len);

/**
 * @brief Delete data from flash storage
 * 
 * Removes the data associated with a key from storage.
 * 
 * @param key Unique identifier for the data
 * @return HAL_OK on success, HAL_ERROR if key not found
 */
int hal_flash_delete(const char *key);

/**
 * @brief Check if a key exists in flash storage
 * 
 * @param key Unique identifier to check
 * @return true if key exists, false otherwise
 */
bool hal_flash_exists(const char *key);

/**
 * @brief Get the size of stored data
 * 
 * Returns the size of data associated with a key without reading it.
 * Useful for allocating buffers before reading.
 * 
 * @param key Unique identifier for the data
 * @return Size in bytes if key exists, HAL_ERROR otherwise
 */
int hal_flash_get_size(const char *key);

/**
 * @brief Get free space available in flash storage
 * 
 * Returns the approximate free space available in the NVS partition.
 * Note: Actual usable space may be less due to wear leveling overhead.
 * 
 * @return Free space in bytes, or HAL_ERROR on failure
 */
int hal_flash_get_free_space(void);

#ifdef __cplusplus
}
#endif

#endif /* OCTROBOT_HAL_FLASH_H */
```

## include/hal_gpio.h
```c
/*
 * OctroBot Robot Arm Firmware - GPIO Utilities
 * Copyright (c) 2026 OctroBot Project
 *
 * SPDX-License-Identifier: Apache-2.0
 */

#ifndef OCTROBOT_HAL_GPIO_H
#define OCTROBOT_HAL_GPIO_H

#include "hal_types.h"

/**
 * @brief Initialize button GPIO (emergency stop)
 *
 * @return HAL_OK on success, error code otherwise
 */
int hal_gpio_button_init(void);

/**
 * @brief Read button state
 *
 * @return true if button is pressed, false otherwise
 */
bool hal_gpio_button_is_pressed(void);

/**
 * @brief Set button callback for emergency stop
 *
 * @param callback Function to call when button is pressed
 * @return HAL_OK on success, error code otherwise
 */
int hal_gpio_button_set_callback(void (*callback)(void));

/**
 * @brief Initialize status LED (WS2812B)
 *
 * @return HAL_OK on success, error code otherwise
 */
int hal_gpio_led_init(void);

/**
 * @brief Set LED state (simple on/off, WS2812B requires special driver for colors)
 *
 * @param on true to turn on, false to turn off
 * @return HAL_OK on success, error code otherwise
 */
int hal_gpio_led_set(bool on);

#endif /* OCTROBOT_HAL_GPIO_H */
```

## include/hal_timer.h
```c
/*
 * OctroBot Robot Arm Firmware - Timer Utilities
 * Copyright (c) 2026 OctroBot Project
 *
 * SPDX-License-Identifier: Apache-2.0
 *
 * Provides microsecond-resolution timing for control loops.
 */

#ifndef OCTROBOT_HAL_TIMER_H
#define OCTROBOT_HAL_TIMER_H

#include "hal_types.h"

/**
 * @brief Get current time in microseconds
 *
 * Uses Zephyr k_cycle_get_32() and converts to microseconds.
 * Wraps around approximately every 71 minutes on 240MHz ESP32.
 *
 * @return Current time in microseconds
 */
uint64_t hal_timer_get_us(void);

/**
 * @brief Get current time in milliseconds
 *
 * @return Current time in milliseconds
 */
uint64_t hal_timer_get_ms(void);

/**
 * @brief Delay for specified microseconds (busy-wait)
 *
 * Use sparingly - prefer k_usleep() for longer delays to allow
 * other threads to run.
 *
 * @param us Microseconds to delay
 */
void hal_timer_delay_us(uint32_t us);

/**
 * @brief Delay for specified milliseconds
 *
 * Uses k_msleep() to yield to other threads.
 *
 * @param ms Milliseconds to delay
 */
void hal_timer_delay_ms(uint32_t ms);

/**
 * @brief Initialize timer subsystem
 *
 * @return HAL_OK on success, error code otherwise
 */
int hal_timer_init(void);

#endif /* OCTROBOT_HAL_TIMER_H */
```

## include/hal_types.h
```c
/*
 * OctroBot Robot Arm Firmware - HAL Common Types
 * Copyright (c) 2026 OctroBot Project
 *
 * SPDX-License-Identifier: Apache-2.0
 */

#ifndef OCTROBOT_HAL_TYPES_H
#define OCTROBOT_HAL_TYPES_H

#include <stdint.h>
#include <stdbool.h>
#include <stddef.h>

/* Return codes */
#define HAL_OK           0
#define HAL_ERROR       -1
#define HAL_TIMEOUT     -2
#define HAL_BUSY        -3
#define HAL_INVALID     -4

/* Opaque handle types for HAL modules */
typedef struct hal_uart_handle_s *hal_uart_handle_t;

#endif /* OCTROBOT_HAL_TYPES_H */
```

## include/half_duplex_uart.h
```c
/*
 * OctroBot Robot Arm Firmware - Half-Duplex UART Driver
 * Copyright (c) 2026 OctroBot Project
 *
 * SPDX-License-Identifier: Apache-2.0
 *
 * Half-duplex UART driver for Feetech servo bus communication.
 * Handles TX/RX direction switching for RS-485-style communication.
 */

#ifndef OCTROBOT_HALF_DUPLEX_UART_H
#define OCTROBOT_HALF_DUPLEX_UART_H

#include "hal_types.h"

/**
 * @brief Half-duplex UART configuration
 */
struct half_duplex_uart_config {
	const char *device_name;        /* Optional Zephyr UART device name (e.g., "UART_1") */
	uint32_t baudrate;              /* Baud rate (e.g., 1000000 for 1 Mbps) */
	uint32_t tx_timeout_ms;         /* Transmit timeout in milliseconds */
	uint32_t rx_timeout_ms;         /* Receive timeout in milliseconds */
};

/**
 * @brief Initialize half-duplex UART
 *
 * @param config Pointer to configuration structure
 * @return hal_uart_handle_t Handle to UART instance, or NULL on error
 */
hal_uart_handle_t half_duplex_uart_init(const struct half_duplex_uart_config *config);

/**
 * @brief Deinitialize half-duplex UART
 *
 * @param handle UART handle
 * @return HAL_OK on success, error code otherwise
 */
int half_duplex_uart_deinit(hal_uart_handle_t handle);

/**
 * @brief Transmit data (blocking with timeout)
 *
 * Automatically switches to TX mode, sends data, waits for completion,
 * then switches back to RX mode.
 *
 * @param handle UART handle
 * @param data Pointer to data buffer
 * @param len Length of data in bytes
 * @return Number of bytes transmitted, or negative error code
 */
int half_duplex_uart_transmit(hal_uart_handle_t handle, const uint8_t *data, size_t len);

/**
 * @brief Receive data (blocking with timeout)
 *
 * @param handle UART handle
 * @param data Pointer to receive buffer
 * @param len Maximum length to receive
 * @param timeout_ms Timeout in milliseconds (0 = use default)
 * @return Number of bytes received, or negative error code
 */
int half_duplex_uart_receive(hal_uart_handle_t handle, uint8_t *data, size_t len,
                              uint32_t timeout_ms);

/**
 * @brief Flush RX buffer
 *
 * @param handle UART handle
 * @return HAL_OK on success, error code otherwise
 */
int half_duplex_uart_flush_rx(hal_uart_handle_t handle);

/**
 * @brief Get number of bytes available in RX buffer
 *
 * @param handle UART handle
 * @return Number of bytes available, or negative error code
 */
int half_duplex_uart_rx_available(hal_uart_handle_t handle);

#endif /* OCTROBOT_HALF_DUPLEX_UART_H */
```

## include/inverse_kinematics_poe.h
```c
/*
 * OctroBot Robot Arm Firmware - Inverse Kinematics (POE, body-frame)
 * Copyright (c) 2026 OctroBot Project
 *
 * SPDX-License-Identifier: Apache-2.0
 *
 * Body-frame Newton-Raphson IK solver (Modern Robotics IKinBody).
 * Offline-validated against the modern_robotics Python library.
 */

#ifndef INVERSE_KINEMATICS_POE_H
#define INVERSE_KINEMATICS_POE_H

#include "kinematics_math.h"
#include "robot_geometry.h"
#include <stdbool.h>

#ifdef __cplusplus
extern "C" {
#endif

/** Outcome of an IK solve. */
typedef enum {
	IK_SUCCESS = 0,    /* converged, all joints within limits      */
	IK_OUT_OF_LIMITS,  /* converged, but >=1 joint out of limits   */
	IK_NO_CONVERGENCE, /* hit max_iters without converging         */
	IK_INVALID_INPUT,  /* NULL argument                            */
} ik_status_t;

/** Solver tuning parameters. */
typedef struct {
	float eomg;      /* angular error tolerance (rad)   */
	float ev;        /* linear error tolerance (m)      */
	int   max_iters; /* maximum Newton-Raphson iterations */
	float lambda;    /* damped-least-squares factor (0 = pure pinv) */
} ik_params_t;

/**
 * Default parameters: eomg=1e-3, ev=1e-4, max_iters=20, lambda=0.0.
 * lambda=0.0 reproduces modern_robotics.IKinBody for clean cross-validation.
 */
ik_params_t inverse_kinematics_default_params(void);

/**
 * Solve IK for a desired end-effector pose.
 *
 * Inputs:
 *   - model:     robot geometry (space-frame screw axes + home config M)
 *   - T_target:  desired end-effector pose T_sd
 *   - seed:      initial joint-angle guess (radians)
 *   - params:    tuning parameters, or NULL for defaults
 * Outputs:
 *   - out_angles:  final joint angles, wrapped to [-pi, pi] (always written)
 *   - iters_used:  iterations performed (optional, may be NULL)
 *
 * Returns an ik_status_t. out_angles always holds the final iterate, even on
 * non-convergence.
 */
ik_status_t inverse_kinematics_compute(const poe_robot_model_t *model,
				       const mat4x4_t *T_target,
				       const float seed[NUM_JOINTS],
				       float out_angles[NUM_JOINTS],
				       const ik_params_t *params,
				       int *iters_used);

#ifdef __cplusplus
}
#endif

#endif /* INVERSE_KINEMATICS_POE_H */
```
